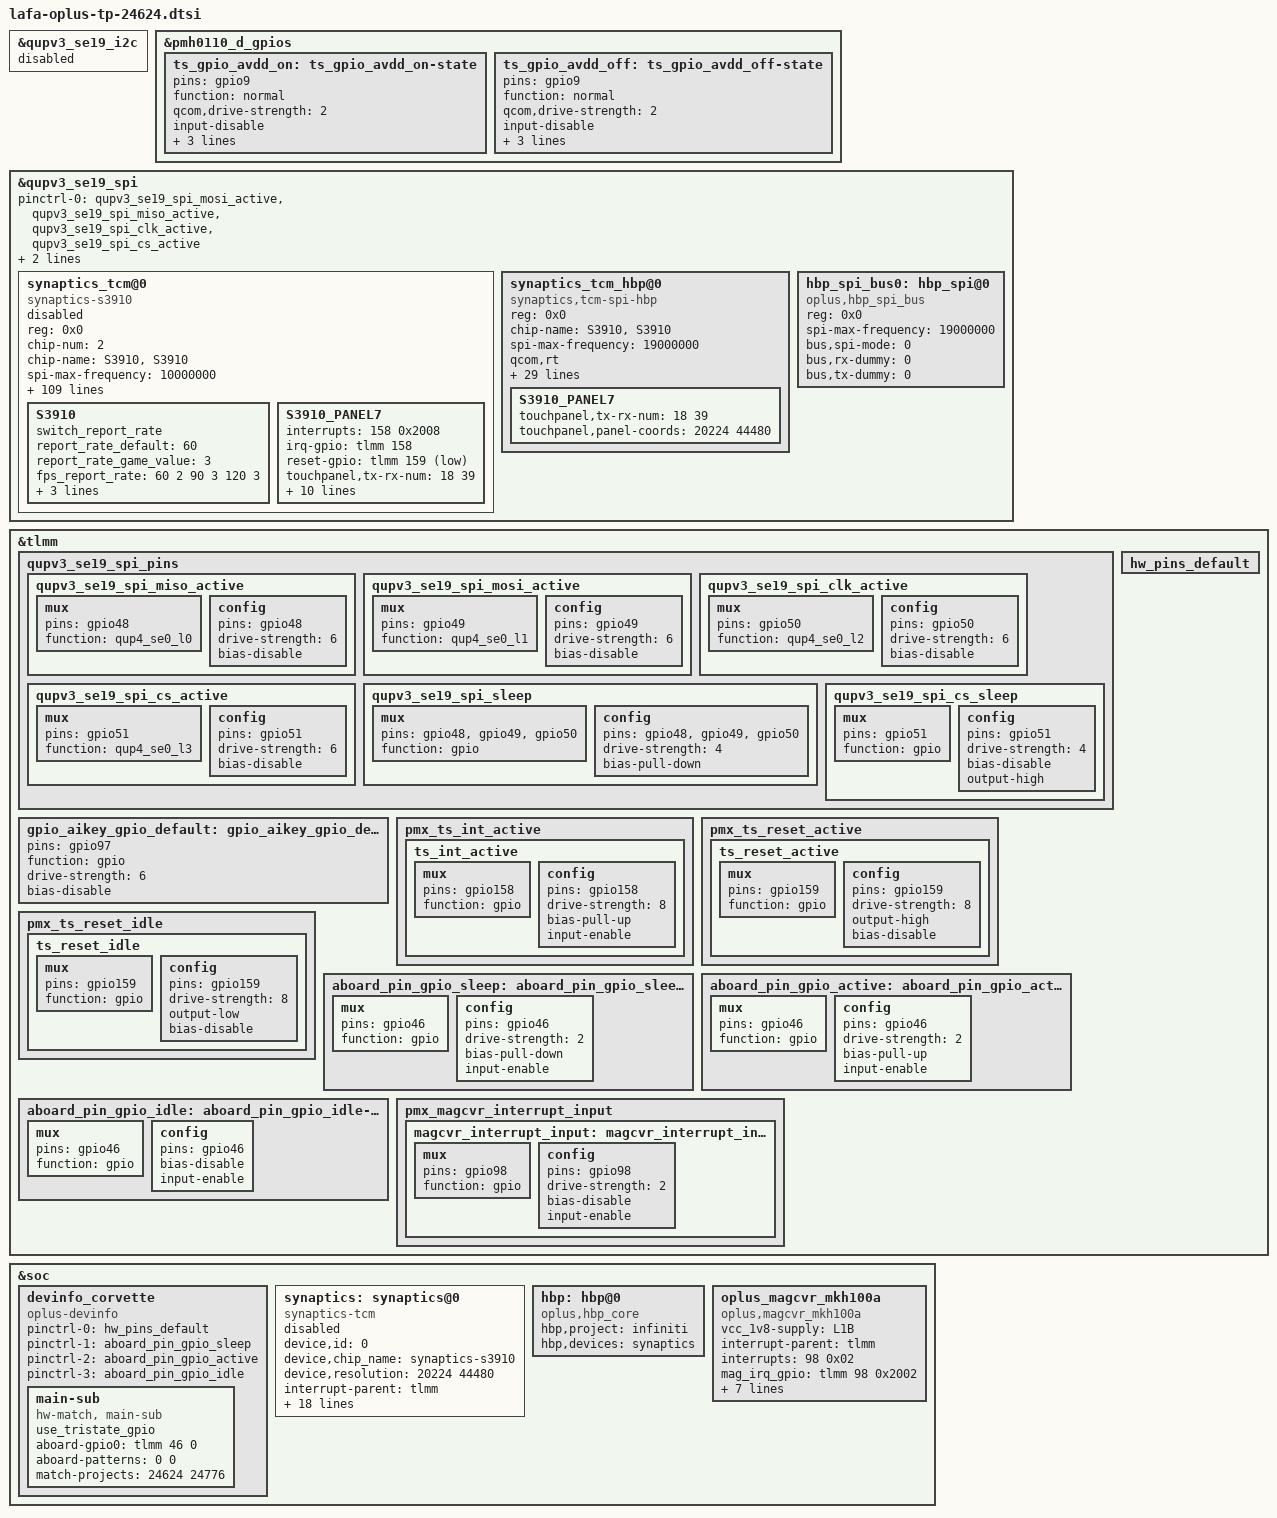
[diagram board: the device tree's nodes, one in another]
&qupv3_se19_i2c {
	status = "disabled";
};

&pmh0110_d_gpios {
	ts_gpio_avdd_on: ts_gpio_avdd_on-state {
		pins = "gpio9";
		function = "normal";
		qcom,drive-strength = <2>;
		input-disable;
		output-enable;
		output-high;
		power-source = <1>;
	};

	ts_gpio_avdd_off: ts_gpio_avdd_off-state {
		pins = "gpio9";
		function = "normal";
		qcom,drive-strength = <2>;
		input-disable;
		output-enable;
		output-low;
		power-source = <1>;
	};

};

&qupv3_se19_spi{
	/delete-property/ pinctrl-0;
	/delete-property/ pinctrl-1;
	pinctrl-0 = <&qupv3_se19_spi_mosi_active>, <&qupv3_se19_spi_miso_active>,
				<&qupv3_se19_spi_clk_active>, <&qupv3_se19_spi_cs_active>;
	pinctrl-1 = <&qupv3_se19_spi_sleep>, <&qupv3_se19_spi_cs_sleep>;
};

&tlmm {
	qupv3_se19_spi_pins: qupv3_se19_spi_pins {
		qupv3_se19_spi_miso_active: qupv3_se19_spi_miso_active {
			mux {
				pins = "gpio48";
				function = "qup4_se0_l0";
			};

			config {
				pins = "gpio48";
				drive-strength = <6>;
				bias-disable;
			};
		};

		qupv3_se19_spi_mosi_active: qupv3_se19_spi_mosi_active {
			mux {
				pins = "gpio49";
				function = "qup4_se0_l1";
			};

			config {
				pins = "gpio49";
				drive-strength = <6>;
				bias-disable;
			};
		};

		qupv3_se19_spi_clk_active: qupv3_se19_spi_clk_active {
			mux {
				pins = "gpio50";
				function = "qup4_se0_l2";
			};

			config {
				pins = "gpio50";
				drive-strength = <6>;
				bias-disable;
			};
		};

		qupv3_se19_spi_cs_active: qupv3_se19_spi_cs_active {
			mux {
				pins = "gpio51";
				function = "qup4_se0_l3";
			};

			config {
				pins = "gpio51";
				drive-strength = <6>;
				bias-disable;
			};
		};

		qupv3_se19_spi_sleep: qupv3_se19_spi_sleep {
			mux {
				pins = "gpio48", "gpio49",
					"gpio50";
				function = "gpio";
			};

			config {
				pins = "gpio48", "gpio49",
					"gpio50";
				drive-strength = <4>;
				bias-pull-down;
			};
		};

		qupv3_se19_spi_cs_sleep: qupv3_se19_spi_cs_sleep {
			mux {
				pins = "gpio51";
				function = "gpio";
			};

			config {
				pins = "gpio51";
				drive-strength = <4>;
				bias-disable;
				output-high;
			};
		};
	};
};

&qupv3_se19_spi {
	#address-cells = <1>;
	#size-cells = <0>;
	status = "ok";

	synaptics_tcm@0{
		compatible = "synaptics-s3910";
		reg = <0x0>;
		chip-num = <2>;
		chip-name = "S3910","S3910";
		status = "disabled";
		spi-max-frequency = <10000000>;

		/* Interrupt && Irq-gpio */
		interrupt-parent = <&tlmm>;
		interrupts = <158 0x2008>;

		/* Power Config */
		enable2v8_gpio = <&pmh0110_d_gpios 9 1>;
		vcc_1v8-supply = <&L4B>;

		/* Other HW Resource */
		irq-gpio = <&tlmm 158 0x2008>;
		reset-gpio = <&tlmm 159 0x1>;
		pinctrl-names = "default";
		pinctrl-0 = <&ts_int_active &ts_reset_active &ts_gpio_avdd_on>;

		touchpanel,max-num-support = <10>;
		touchpanel,tx-rx-num = <18 39>;
		earsense,tx-rx-num = <18 39>;
		touchpanel,panel-coords = <14400 31360>;
		touchpanel,display-coords = <1440 3136>;
		touchpanel,touchmajor-limit = <256 256>;
		touchpanel,int-mode = <1>; /*0: interrupt and disable, 1:interrupt and not disable*/
		touchpanel,curved-size = <45>;

		prevention,curved_screen_V2;
		prevention,grip_disable_level = <6>;
		prevention,updelay_time_ms = <30>;
		prevention,makeup_cnt_weight = <4 1 2 2 2>;
		prevention,large_corner_range = <2564 6217>;
		prevention,large_corner_judge_condition = <500 300 2194 7 7>;
		prevention,trx_reject_condition = <8 7 7>;
		prevention,trx_strict_reject_condition = <8 6 6>;
		prevention,large_judge_time_ms = <500 50 30>;
		prevention,large_exit_condition = <8 8 2>;
		prevention,single_channel_width = <320 320>;
		prevention,normal_tap_condition = <10 350>;
		prevention,long_edge_condition = <179 90 120 80>;
		prevention,long_strict_edge_condition = <160 60>;
		prevention,long_fingerhold_condition = <70 6 4 4>;
		prevention,short_edge_condition = <179 90 120 80>;
		prevention,short_strict_edge_condition = <160 60>;
		prevention,large_strict_exit_condition = <6 6>;
		prevention,top_corner_config = <464 1371 1000>;
		prevention,edge_swipe_config = <340 1130>;

		prevention,curved_screen_V4;
		prevention,long_eliminate_point_type = <2 23040 16896 445 50688 300 1>;
		prevention,long_fingerhold_condition2 = <1300 3657 0 0>;
		prevention,top_corner_config2 = <3 80 600 1500 0>;
		prevention,hor_long_top_corner_config = <557 3657 0 0>;
		prevention,top_middle_config = <23040 1858 1858 0>;
		prevention,corner_eliminate_point_type = <0 3400 4150 1>;
		prevention,finger_hold_differ_size = <1 0 400 300>;
		prevention,finger_hold_max_rx_exit_distance = <5 650 4205>;
		prevention,max_rx_exit_distance = <1 5 150 650 3657>;
		prevention,dynamic_finger_hold_exit_distance = <1 650 4205 836>;
		prevention,edge_sliding_matched_support = <1 150 3 0>;

		//grip v4.2 reclining mode
		prevention,reclining_mode_support = <1>;
		prevention,long_eliminate_point_type_recli = <2 23040 16896 160 50688 500 1>;
		prevention,finger_hold_differ_size_recli = <1 0 180 400>;
		prevention,finger_hold_max_rx_exit_distance_recli = <4 160 1000>;
		prevention,max_rx_exit_distance_recli = <1 4 100 160 800>;
		prevention,dynamic_finger_hold_exit_distance_recli = <1 160 1000 320>;
		prevention,edge_sliding_matched_support_recli = <1 200 3 0>;

		touchpanel,smooth-level = <0 1 2 4 7 9>;
		touchpanel,smooth-level-charging = <0 2 4 7 8 9>;
		touchpanel,sensitive-level = <0 70 55 40 25 10>;
		touchpanel,single-optimized-time = <8>;
		touchpanel,high-frame-rate-time = <60>;

		end_stretch_value = <480 250 16 16>;
		touchpanel,tp_ic_type = <2>;
		panel_type = <3 7>; /*type:3 BOE  7 TIANMA*/
		// type of tp_dev ,TP-SAMSUNG = 8;
		platform_support_project = <24624 24776>;
		platform_support_project_dir = <24624 24624>;
		platform_support_project_commandline = "mdss_dsi_panel_AE084_P_3_A0033_dsc_cmd","mdss_dsi_panel_AE084_P_7_A0020_dsc_cmd";

		/* SW Support Feature Control */
		black_gesture_support;
		//fw_edge_limit_support;
		pressure_report_support;
		charger_pump_support;
		game_switch_support;
		smart_gesture_support;
		fw_update_app_support;
		fingerprint_underscreen_support;
		freq_hop_simulate_support;
		report_flow_unlock_support;
		screenoff_fingerprint_info_support;
		irq_need_dev_resume_ok;
		//firmware_in_dts;
		//enable_point_auto_change;
		kernel_grip_support;
		//grip_no_driver_support;
		health_monitor_support;
		black_gesture_indep_support;
		exception_upload_support;
		sportify_aod_gesture_support;
		glove_mode_support;
		fingerprint_not_report_in_suspend;
		snr_read_support;
		//temperature_detect_support;
		palm_to_sleep_support;
		tp_data_record_support;
		skip_reinit_device_support;

		/*
		 *Virtual Key Config:
		 *1:touchpanel,button-type: <virtualkey_type  supportted_button-map>
		 *virtualkey_type:
		 *Type 1: using board_properties
		 *Type 2: using same IC (button zone&& touch zone are seprate)
		 *Type 3: using diffrent IC (button zone&& touch zone are seprate)
		 *Type 4: No need of virtual key process
		 *supportted_button-map:select|menu|home|back
		 *
		 *2:touchpanel,button-map
		 *type (X1,Y1)(X2,Y2)(X3,Y3)(Width_X,Hight_Y)--Only when button-type is 0
		 */
		touchpanel,button-type = <4>;
		touchpanel.button-TRx = <0 0>;

		S3910 {
			switch_report_rate;
			report_rate_default = <60>;
			report_rate_game_value = <3>;
			fps_report_rate = <60 2 90 3 120 3>;//1:360Hz 2:125Hz 3:240Hz
			default_gesture_mask = <8191>;
			fwupdate_bootloader = <1>;
			normal_config_version = <2>;
		};

		S3910_PANEL7 {
			interrupts = <158 0x2008>;
			irq-gpio = <&tlmm 158 0x2008>;
			reset-gpio = <&tlmm 159 0x1>;

			touchpanel,tx-rx-num = <18 39>;
			touchpanel,display-coords = <1264 2780>;
			touchpanel,panel-coords = <12640 27800>;
			touchpanel,touchmajor-limit = <256 256>;
			touchpanel,int-mode = <1>; /*0: interrupt and disable, 1:interrupt and not disable*/
			touchpanel,curved-size = <45>;
			touchpanel,smooth-level = <0 1 2 4 7 9>;
			touchpanel,smooth-level-charging = <0 2 4 7 8 9>;
			touchpanel,sensitive-level = <0 70 55 40 25 10>;
			touchpanel,single-optimized-time = <8>;
			touchpanel,high-frame-rate-time = <60>;

		};

	};
	synaptics_tcm_hbp@0{
		compatible = "synaptics,tcm-spi-hbp";
		reg = <0x0>;
		chip-name = "S3910","S3910";
		status = "okay";
		spi-max-frequency = <19000000>;
		qcom,rt;

		/* Interrupt && Irq-gpio */
		interrupt-parent = <&tlmm>;
		interrupts = <158 0x2008>;

		/* Power Config */
		synaptics,avdd-gpio = <&pmh0110_d_gpios 9 0x1>;
		vdd-supply = <&L4B>;
		synaptics,vdd-name = "vdd";

		/* Other HW Resource */
		synaptics,irq-gpio = <&tlmm 158 0x2008>;
		synaptics,reset-gpio = <&tlmm 159 0x1>;
		pinctrl-names = "default";
		pinctrl-0 = <&ts_int_active &ts_reset_active>;

		touchpanel,panel-coords = <23040 50176>;
		touchpanel,tx-rx-num = <18 39>;
		touchpanel,tp_ic_type = <2>;
		panel_type = <3 7>; /*type:3 BOE  7 TIANMA*/
		//firmware_name = "AA601";
		platform_support_project = <24624 24776>;
		platform_support_project_dir = <24624 24624>;
		platform_support_project_commandline = "mdss_dsi_panel_AE084_P_3_A0033_dsc_cmd","mdss_dsi_panel_AE084_P_7_A0020_dsc_cmd";
		synaptics,power-on-state = <1>;
		synaptics,power-delay-ms = <200>;
		synaptics,irq-on-state = <0>;
		synaptics,reset-on-state = <0>;
		synaptics,reset-active-ms = <10>;
		synaptics,reset-delay-ms = <80>;
		synaptics,spi-mode = <0>;
		synaptics,spi-byte-delay-us = <0>;
		synaptics,spi-block-delay-us = <0>;

		/* SW Support Feature Control */
		tp_data_record_support;
		stats_upload_support;
		spi-cs-setup = <50 0>;

		S3910_PANEL7 {
			touchpanel,tx-rx-num = <18 39>;
			touchpanel,panel-coords = <20224 44480>;
		};
	};

	hbp_spi_bus0:hbp_spi@0 {
		compatible = "oplus,hbp_spi_bus";
		reg = <0x0>;
		status = "okay";

		spi-max-frequency = <19000000>;
		bus,spi-mode = <0>;
		bus,rx-dummy = <0>;
		bus,tx-dummy = <0>;
	};


};

//&soc {
//	gpio-hall-sensor {
//		compatible = "gpio-keys";
//		label = "gpio-keys";
//		status = "okay";
//		pinctrl-0 = <&gpio_aikey_gpio_default>;
//		pinctrl-names = "default";
//		oplus-magic-buttom {
//			label = "oplus_magic_buttom";
//			gpios = <&tlmm 97 GPIO_ACTIVE_LOW>;
//			linux,input-type = <EV_KEY>;
//			linux,code = <735>; /* means: BTN_TRIGGER_HAPPY32 */
//			linux,can-disable;
//			gpio-key,wakeup;
//			debounce-interval = <32>; /* standard debounce time 32ms */
//		};
//	};
//};

&tlmm {
		gpio_aikey_gpio_default: gpio_aikey_gpio_default-state {
			pins = "gpio97";
			function = "gpio";
			drive-strength = <6>;
			bias-disable;
		};

		pmx_ts_int_active {
		ts_int_active: ts_int_active {
			mux {
				pins = "gpio158";
				function = "gpio";
			};

			config {
				pins = "gpio158";
				drive-strength = <8>;
				bias-pull-up;
				input-enable;
			};
		};
	};

	pmx_ts_reset_active {
		ts_reset_active: ts_reset_active {
			mux {
				pins = "gpio159";
				function = "gpio";
			};

			config {
				pins = "gpio159";
				drive-strength = <8>;
				output-high;
				bias-disable;
			};
		};
	};

	pmx_ts_reset_idle {
		ts_reset_idle: ts_reset_idle {
			mux {
				pins = "gpio159";
				function = "gpio";
			};

			config {
				pins = "gpio159";
				drive-strength = <8>;
				output-low;
				bias-disable;
			};
		};
	};
};

&soc {
	devinfo_corvette {
		compatible = "oplus-devinfo";
		pinctrl-names = "default", "sleep", "active", "idle";
		pinctrl-0 = <&hw_pins_default>;
		pinctrl-1 = <&aboard_pin_gpio_sleep>;
		pinctrl-2 = <&aboard_pin_gpio_active>;
		pinctrl-3 = <&aboard_pin_gpio_idle>;

		main-sub {
			use_tristate_gpio;
			compatible = "hw-match, main-sub";
			aboard-gpio0 = <&tlmm 46 0>;
			aboard-patterns = <0 0>;	/*0[high-resistance] 1[pull-down] 2[pull-up]*/
			/*main board*/
			match-projects = <24624 24776>;
		};
	};
	synaptics:synaptics@0 {
		compatible = "synaptics-tcm";
		status = "disabled";

		device,id = <0>;
		device,chip_name = "synaptics-s3910";
		device,resolution = <20224 44480>;

		/*interrupt config*/
		interrupt-parent = <&tlmm>;
		interrupts = <158 0x2008>;
		irq-gpio = <&tlmm 158 0x2008>;

		pinctrl-names = "default",
				"ts_reset_active",
				"ts_reset_idle",
				"ts_resume",
				"ts_suspend",
				"ts_avdd_on",
				"ts_avdd_off";
		pinctrl-0 = <&ts_int_active &ts_reset_active>;
		pinctrl-1 = <&ts_reset_active>;
		pinctrl-2 = <&ts_reset_idle>;
		pinctrl-3 = <&qupv3_se19_spi_mosi_active &qupv3_se19_spi_miso_active &qupv3_se19_spi_clk_active &qupv3_se19_spi_cs_active>;
		pinctrl-4 = <&qupv3_se19_spi_sleep &qupv3_se19_spi_cs_sleep>;
		pinctrl-5 = <&ts_gpio_avdd_on>;
		pinctrl-6 = <&ts_gpio_avdd_off>;

		/*cs active state, not used now*/
		spi,cs_active = <0>;

		/*power config*/
		//power,avdd-supply = <&L22B>;
		//power,avdd_volt = <3000000 3000000>;

		power,vddi-supply = <&L4B>;
		power,vddi_volt = <1800000 1800000>;

		/*bus config*/
		device,attached_bus = <&hbp_spi_bus0>;

		create_with_power_on_support;
	};

	hbp:hbp@0 {
		compatible = "oplus,hbp_core";
		hbp,project = "infiniti";
		hbp,devices = <&synaptics>;
	};
};

&tlmm {
	hw_pins_default:hw_pins_default {
	};
	aboard_pin_gpio_sleep:aboard_pin_gpio_sleep-state {
		mux {
			pins = "gpio46";
			function = "gpio";
		};
		config {
			pins = "gpio46";
			drive-strength = <2>;
			bias-pull-down;
			input-enable;
		};
	};

	aboard_pin_gpio_active:aboard_pin_gpio_active-state {
		mux {
			pins = "gpio46";
			function = "gpio";
		};
		config {
			pins = "gpio46";
			drive-strength = <2>;
			bias-pull-up;
			input-enable;
		};
	};

	aboard_pin_gpio_idle:aboard_pin_gpio_idle-state {
		mux {
			pins = "gpio46";
			function = "gpio";
		};
		config {
			pins = "gpio46";
			bias-disable;
			input-enable;
		};
	};
};

&soc {
	oplus_magcvr_mkh100a {
		status = "ok";
		compatible = "oplus,magcvr_mkh100a";
		vcc_1v8-supply = <&L1B>;
		// vcc_3v0-supply = <&mt6368_vio28>;
		// vdd_3v0_volt = <3100000>;
		interrupt-parent = <&tlmm>;
		interrupts = <98 0x02>;
		mag_irq_gpio = <&tlmm 98 0x2002>;
		pinctrl-names = "default";
		pinctrl-0 = <&magcvr_interrupt_input>;
		// para config
		magcvr_detect_step = <50>;
		magcvr_farmax_th = <50>;
		magcvr_far_threshold = <150>;
		magcvr_far_noise_threshold = <125>;
		magcvr_irq_type = <4>;
		no_need_calibration;
	};
};

&tlmm {
	pmx_magcvr_interrupt_input {
		magcvr_interrupt_input: magcvr_interrupt_input-state {
			mux {
				pins = "gpio98";
				function = "gpio";
			};

			config {
				pins = "gpio98";
				drive-strength = <2>;
				bias-disable;
				input-enable;
			};
		};
	};
};


